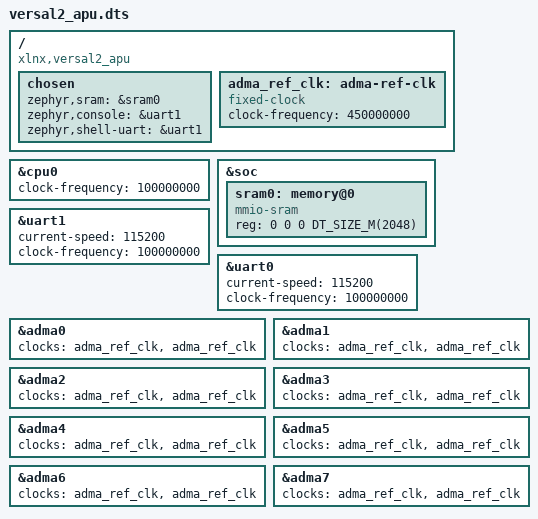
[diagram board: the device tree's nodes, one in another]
/*
 * Copyright (c) 2025, Advanced Micro Devices, Inc.
 *
 * SPDX-License-Identifier: Apache-2.0
 */

/dts-v1/;
#include <arm64/xilinx/versal2_a78.dtsi>

/ {
	compatible = "xlnx,versal2_apu";

	chosen {
		zephyr,sram = &sram0;
		zephyr,console = &uart1;
		zephyr,shell-uart = &uart1;
	};

	adma_ref_clk: adma-ref-clk {
		compatible = "fixed-clock";
		#clock-cells = <0>;
		clock-frequency = <450000000>;
	};
};

&cpu0 {
	clock-frequency = <100000000>;
};

&soc {
	sram0: memory@0 {
		compatible = "mmio-sram";
		reg = <0 0 0 DT_SIZE_M(2048)>;
	};
};

&uart1 {
	current-speed = <115200>;
	clock-frequency = <100000000>;
	status = "okay";
};

&uart0 {
	current-speed = <115200>;
	clock-frequency = <100000000>;
	status = "okay";
};

&adma0 {
	clocks = <&adma_ref_clk>, <&adma_ref_clk>;
	status = "okay";
};

&adma1 {
	clocks = <&adma_ref_clk>, <&adma_ref_clk>;
	status = "okay";
};

&adma2 {
	clocks = <&adma_ref_clk>, <&adma_ref_clk>;
	status = "okay";
};

&adma3 {
	clocks = <&adma_ref_clk>, <&adma_ref_clk>;
	status = "okay";
};

&adma4 {
	clocks = <&adma_ref_clk>, <&adma_ref_clk>;
	status = "okay";
};

&adma5 {
	clocks = <&adma_ref_clk>, <&adma_ref_clk>;
	status = "okay";
};

&adma6 {
	clocks = <&adma_ref_clk>, <&adma_ref_clk>;
	status = "okay";
};

&adma7 {
	clocks = <&adma_ref_clk>, <&adma_ref_clk>;
	status = "okay";
};
